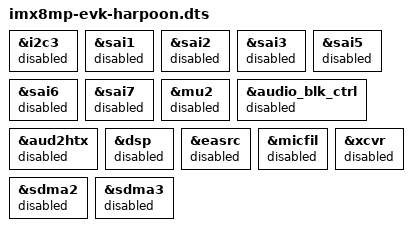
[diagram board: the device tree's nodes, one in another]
// SPDX-License-Identifier: (GPL-2.0+ OR MIT)
/*
 * Copyright 2021-2023, 2025 NXP
 */

#include "imx8mp-evk-root.dts"
#include "imx8mp-rpmsg-ca53.dtsi"

&i2c3 {
	status = "disabled";
};

/* Disable the whole Audio system for Linux and give full ownership to RTOS. */
&sai1 {
	status = "disabled";
};

&sai2 {
	status = "disabled";
};

&sai3 {
	status = "disabled";
};

&sai5 {
	status = "disabled";
};

&sai6 {
	status = "disabled";
};

&sai7 {
	status = "disabled";
};

&mu2 {
	status = "disabled";
};

&audio_blk_ctrl {
	status = "disabled";
};

&aud2htx {
	status = "disabled";
};

&dsp {
	status = "disabled";
};

&easrc {
	status = "disabled";
};

&micfil {
	status = "disabled";
};

&sdma2 {
	status = "disabled";
};

&sdma3 {
	status = "disabled";
};

&xcvr {
	status = "disabled";
};
